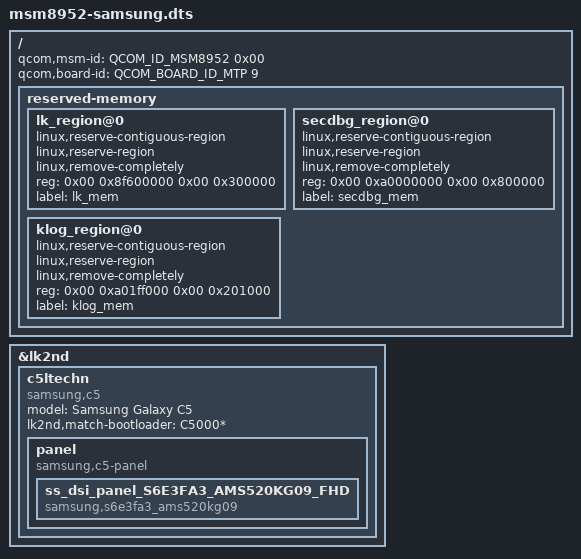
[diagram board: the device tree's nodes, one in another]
/dts-v1/;

#include <skeleton64.dtsi>
#include <lk2nd.dtsi>

/*
 * To build for samsung devices, add LK2ND_QCDTBS="msm8952-samsung.dtb" to
 * your make cmdline.
 * samsung bootloader really want images built with embedded QCDT
 * otherwise the bootloader yell as you "Can't get fdt"
 * and goes into the phone's odin.
 */

/ {
	
	qcom,msm-id = <QCOM_ID_MSM8952 0x00>;
	qcom,board-id = <QCOM_BOARD_ID_MTP 9>;

	/* bootloader refuses the dtb if the dtb dont have reserved-memory */

	reserved-memory {
		lk_region@0 {
			linux,reserve-contiguous-region;
			linux,reserve-region;
			linux,remove-completely;
			reg = <0x00 0x8f600000 0x00 0x300000>;
			label = "lk_mem";
		};

		secdbg_region@0 {
			linux,reserve-contiguous-region;
			linux,reserve-region;
			linux,remove-completely;
			reg = <0x00 0xa0000000 0x00 0x800000>;
			label = "secdbg_mem";
		};

		klog_region@0 {
			linux,reserve-contiguous-region;
			linux,reserve-region;
			linux,remove-completely;
			reg = <0x00 0xa01ff000 0x00 0x201000>;
			label = "klog_mem";
		};
	};

};

&lk2nd {
	c5ltechn {
		model = "Samsung Galaxy C5";
		compatible = "samsung,c5";
		lk2nd,match-bootloader = "C5000*";

		panel {
			compatible = "samsung,c5-panel", "lk2nd,panel";
			ss_dsi_panel_S6E3FA3_AMS520KG09_FHD {
				compatible = "samsung,s6e3fa3_ams520kg09";
			};
		};

	};
};
